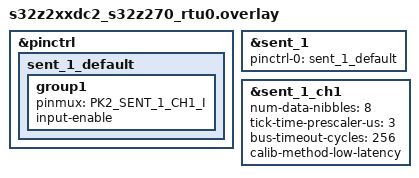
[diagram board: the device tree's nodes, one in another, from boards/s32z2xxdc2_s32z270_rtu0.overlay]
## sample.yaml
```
sample:
  description: Sample for using SENT driver
  name: NXP S32 SENT sample

tests:
  sample.boards.nxp_s32.sent:
    platform_allow:
      - s32z2xxdc2/s32z270/rtu0
      - s32z2xxdc2/s32z270/rtu1
      - s32z2xxdc2@D/s32z270/rtu0
      - s32z2xxdc2@D/s32z270/rtu1
    depends_on: sent
    tags: sent
    harness: console
```

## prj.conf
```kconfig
CONFIG_SENT=y
CONFIG_SENT_LOG_LEVEL_DBG=y
CONFIG_LOG=y
CONFIG_LOG_MODE_MINIMAL=y
```

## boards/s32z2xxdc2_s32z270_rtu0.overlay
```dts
/*
 * Copyright 2024 NXP
 *
 * SPDX-License-Identifier: Apache-2.0
 */

&pinctrl {
	sent_1_default: sent_1_default {
		group1 {
			pinmux = <PK2_SENT_1_CH1_I>;
			input-enable;
		};
	};
};

&sent_1 {
	pinctrl-0 = <&sent_1_default>;
	pinctrl-names = "default";
	status = "okay";
};

&sent_1_ch1 {
	num-data-nibbles = <8>;
	tick-time-prescaler-us = <3>;
	bus-timeout-cycles = <256>;
	calib-method-low-latency;
	status = "okay";
};
```

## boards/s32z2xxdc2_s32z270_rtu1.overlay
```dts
/*
 * Copyright 2024 NXP
 *
 * SPDX-License-Identifier: Apache-2.0
 */

&pinctrl {
	sent_1_default: sent_1_default {
		group1 {
			pinmux = <PK2_SENT_1_CH1_I>;
			input-enable;
		};
	};
};

&sent_1 {
	pinctrl-0 = <&sent_1_default>;
	pinctrl-names = "default";
	status = "okay";
};

&sent_1_ch1 {
	num-data-nibbles = <6>;
	tick-time-prescaler-us = <3>;
	bus-timeout-cycles = <256>;
	calib-method-low-latency;
	status = "okay";
};
```

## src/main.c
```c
/*
 * Copyright 2024 NXP
 *
 * SPDX-License-Identifier: Apache-2.0
 */

#include <zephyr/logging/log.h>
LOG_MODULE_REGISTER(nxp_s32_sent_sample, LOG_LEVEL_DBG);

#include <zephyr/kernel.h>

#include <zephyr/drivers/sent/sent.h>

#define SENT_NODE DT_INST(0, nxp_s32_sent)

void rx_cb(const struct device *dev, uint8_t channel_id, struct sent_frame *frame,
	   enum sent_state state, void *user_data)
{
	LOG_INF("rx ch %d", channel_id);
}

int main(void)
{
	const struct device *const dev = DEVICE_DT_GET(SENT_NODE);

	sent_add_rx_callback(dev, 1, rx_cb, NULL);

	sent_start(dev, 1);

	return 0;
}
```
